# TOP_EFUSE_FARM_TOP_EFUSE_FARM register map
Vendor: Texas Instruments
Peripheral module from a debugger description file (folder AM263).
Registers are 32-bit, access per field, reset values left out (the file's numbers can be read two ways) unless marked. A register's access mark holds for its fields unless they carry their own. Offsets are as the file gives them; lines under a group give offsets from that group; [hi:lo] are bit positions; {n}, {i} and the like mark numbered series; 'fields as' and 'values as' point back to an identical list; <NAME> marks a mode.

## TOP_EFUSE_FARM_TOP_EFUSE_FARM
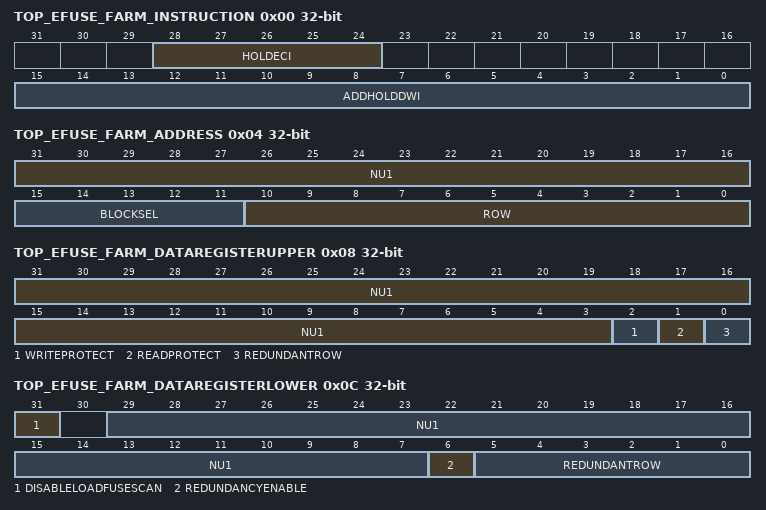
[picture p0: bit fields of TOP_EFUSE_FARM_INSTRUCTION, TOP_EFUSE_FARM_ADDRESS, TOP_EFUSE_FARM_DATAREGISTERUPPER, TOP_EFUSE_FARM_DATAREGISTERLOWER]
0x00 TOP_EFUSE_FARM_INSTRUCTION rw
  [28:24] HOLDECI — Holds the eFuse controller instruction.
  [15:0] ADDHOLDDWI — Holds the address to use for the DumpWord instruction. All other instructions ignore these bits.
0x04 TOP_EFUSE_FARM_ADDRESS
  [31:16] NU1 ro — Not used
  [15:11] BLOCKSEL rw — FuseROM block select. These five bits select which of the 32 possible FuseROMs is used in the following instruction.
  [10:0] ROW rw — FuseROM row address. Given the FuseROM selected by the FuseROM block select, these 11 bits select which row of the FuseROM is used in the following instruction. Since the maximum number of rows for a FuseROM is 64, only bits [5:0] of the FuseROM row address should be used. Address bits [10:6] should be set low ('0')
0x08 TOP_EFUSE_FARM_DATAREGISTERUPPER
  [31:3] NU1 ro — Not used
  [2] WRITEPROTECT rw — Write protect (WP). Once this bit is set high ('1') in any FuseROM row, the other bits in that FuseROM row can no longer be programmed.
  [1] READPROTECT rw — Read protect (RP). Once this bit is set high ('1') in any FuseROM row, a DumpWord instruction returns all zeros (00000000H). The actual data in bits [31:0] of that row will still be loaded into the fuse scan chain during an autoload operation.
  [0] REDUNDANTROW rw — row 0 - Not used row 1 - 63 Redundant (R). Once this bit is set high (?1?), the row is marked as having a failure and is replaced by a redundant row.
0x0C TOP_EFUSE_FARM_DATAREGISTERLOWER
  [31] DISABLELOADFUSESCAN rw — Disable LoadFuseScanChain. If this bit is programmed, the LoadFuseScanChain operation (also called soft load operation) is disabled.
  [29:7] NU1 ro — Not used
  [6] REDUNDANCYENABLE rw — Redundancy enable. If a redundant row address is programmed in bits[5:0], this bit must be programmed.
  [5:0] REDUNDANTROW rw — Redundant row address. These six bits contain the address of a failing row that will be replaced by the native redundant row physically located at the bottom of FuseROM array.
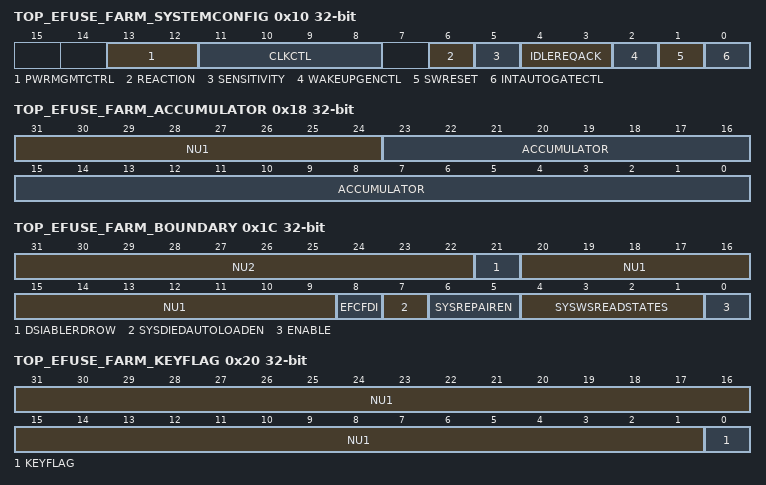
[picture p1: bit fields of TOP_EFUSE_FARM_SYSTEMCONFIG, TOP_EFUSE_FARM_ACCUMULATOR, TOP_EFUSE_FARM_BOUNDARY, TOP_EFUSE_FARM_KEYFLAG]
0x10 TOP_EFUSE_FARM_SYSTEMCONFIG rw
  [13:12] PWRMGMTCTRL — Master interface power management control
  [11:8] CLKCTL — Control of clock internal gating while module is idle. There is one bit per clock. The actual register width depends on the number of functional clocks controlled.
  [6] REACTION — Reaction to module suspend assertion (for emulation). There is no effect if bit[5]=1.
  [5] SENSITIVITY — Sensitivity to module suspend (for emulation).
  [4:3] IDLEREQACK — Slave interface power management control. Idle request/acknowledge control.
  [2] WAKEUPGENCTL — Asynchronous wake-up generation control
  [1] SWRESET — Module software reset
  [0] INTAUTOGATECTL — Internal autogating control.
0x14 TOP_EFUSE_FARM_SYSTEMSTATUS rw
  [0] RESETDONE
0x18 TOP_EFUSE_FARM_ACCUMULATOR
  [31:24] NU1 ro — Not used
  [23:0] ACCUMULATOR rw — Accumulator. These bits hold data after the execution of various instructions.
0x1C TOP_EFUSE_FARM_BOUNDARY
  [31:22] NU2 ro — Not used
  [21] DSIABLERDROW rw — Disable read row 0. When high, disables read of row 0 during initial access of FuseROM.
  [20:9] NU1 ro — Not used
  [8] EFCFDI rw — EFC_FDI. This bit drives the EFC_FDI input when enable is set.
  [7] SYSDIEDAUTOLOADEN rw — SYS_DIEID_AUTOLOAD_EN. This bit drives the SYS_DIEID_AUTOLOAD_EN input when enable is set.
  [6:5] SYSREPAIREN rw — SYS_REPAIR_EN[1:0]. This bus sets the SYS_REPAIR_EN inputs when enable is set.
  [4:1] SYSWSREADSTATES rw — SYS_WS_READ_STATES[3:0]. These bits drive the SYS_WS_READ_STATES inputs when enable is set.
  [0] ENABLE rw — Enable. This bit is used to control whether the input ports or the boundary register drives the inputs. If set high (?1?), the inputs to the controller are driven by the values of the boundary register.
0x20 TOP_EFUSE_FARM_KEYFLAG
  [31:1] NU1 ro — Not used
  [0] KEYFLAG rw — Key flag. If the proper key is loaded into the key code bits, this bit will read a 1.
0x24 TOP_EFUSE_FARM_KEY rw
  [31:0] KEYCODE — Key code. These 32 bits are used to set the key (96969696h) for the program instruction.
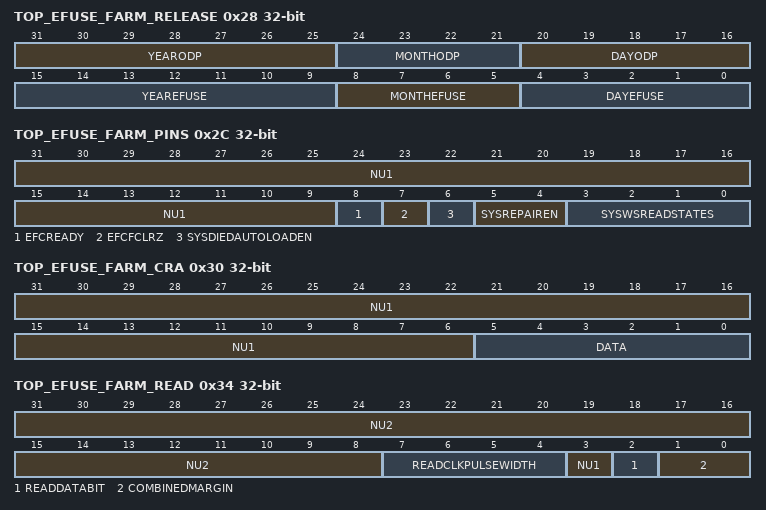
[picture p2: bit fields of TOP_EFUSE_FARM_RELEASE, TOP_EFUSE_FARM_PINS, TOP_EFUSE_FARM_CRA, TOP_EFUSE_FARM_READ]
0x28 TOP_EFUSE_FARM_RELEASE rw
  [31:25] YEARODP — Release code indicating year of ODP controller macro release.
  [24:21] MONTHODP — Release code indicating month of ODP controller macro release.
  [20:16] DAYODP — Release code indicating day of ODP controller macro release.
  [15:9] YEAREFUSE — Release code indicating year of eFuse controller macro release.
  [8:5] MONTHEFUSE — Release code indicating month of eFuse controller macro release.
  [4:0] DAYEFUSE — Release code indicating day of eFuse controller macro release.
0x2C TOP_EFUSE_FARM_PINS
  [31:9] NU1 ro — Not used
  [8] EFCREADY rw — EFC_READY. Output pin.
  [7] EFCFCLRZ rw — EFC_FCLRZ. Output pin.
  [6] SYSDIEDAUTOLOADEN rw — SYS_DIEID_AUTOLOAD_EN. Input pin.
  [5:4] SYSREPAIREN rw — SYS_REPAIR_EN[1:0]. Input pins.
  [3:0] SYSWSREADSTATES rw — SYS_WS_READ_STATES[3:0]. Input pin.
0x30 TOP_EFUSE_FARM_CRA
  [31:6] NU1 ro — Not used
  [5:0] DATA rw — Data bits to be programmed into the CRA bits of the addressed row
0x34 TOP_EFUSE_FARM_READ
  [31:8] NU2 ro — Not used
  [7:4] READCLKPULSEWIDTH rw — ROM clock read pulse width. Active high. Specifies the number of internal clock cycles that the FuseROM clock (pin FROM_CLK) is high ('1'). These bits override the SYS_WS_READ_STATE[3:0] ports. Values are: Bit Width (4b'0000) 1 * SYS_CLK period (4b'0001) 1 * SYS_CLK period (4b'0010) 2 * SYS_CLK period (4b'0011) 3 * SYS_CLK period (4b'0100) 4 * SYS_CLK period (4b?0101) 5 * SYS_CLK period (4b?0110) - (4b?1111) Not used
  [3] NU1 ro — Reserved for FuseROM testing and debugging.
  [2] READDATABIT rw — Read data bit. If the read protect (RP) bit is set in any row, only RP and the write protect (WP) bit are reported during a read, and the other bits are zero. If the RP bit is not set, and the repair (R) bit is set: If read register[2] = 0 (default), then a read command reads data from the redundant repair row. . If read register[2] = 1, then a read command reads data from the original address row.
  [1:0] COMBINEDMARGIN rw — Combined margin. The bits set the sense amp margin limits according to the following table. The FuseROM Compiler section in the GS60 Customer In-field Programmable FuseROM specification shows more information on combined margin. Margin(1:0) Trip Point Label Description 00 5K Normal Normal read 01 2K Margin 0 Margin test for unblown fuses. An unblown fuse should have a resistance below the trip point. 10 22K Margin 1A Margin test for blown fuses. Higher compare resistance than normal. 11 60K Margin 1B Margin test for blown fuses. Higher margin resistance than normal or Margin 1A.
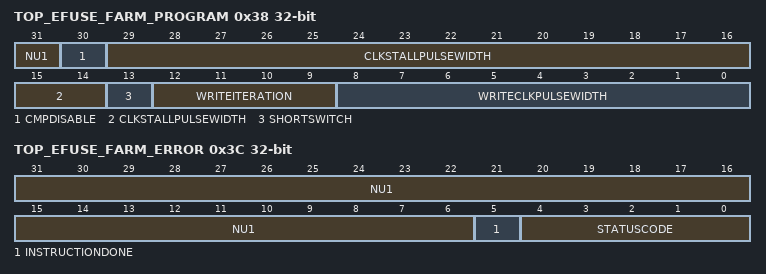
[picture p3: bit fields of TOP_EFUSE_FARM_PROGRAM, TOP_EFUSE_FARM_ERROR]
0x38 TOP_EFUSE_FARM_PROGRAM
  [31] NU1 ro — Not used
  [30] CMPDISABLE rw — Compare disable. Before any FuseROM bit is actually blown, the value of the data register is compared to the FuseROM data bits in the row selected by the address register. If the data register is already equal to the FuseROM row data, the row is not blown, and the program instruction is aborted. Error code 5b 01101 (for more information, see FuseFarm error codes) is placed on EFC_ERROR ports. To avoid this and force the program instruction to continue, set this bit to 1.
  [29:14] CLKSTALLPULSEWIDTH rw — 16-bit FuseROM clock stall pulse width. Active low. After the controller attempts to program the data register value into the FuseROM row selected by the address register, the FROM_CLK signal is held low (?0?) for a specified number of internal clock cycles to separate each pass of the controller. These bits determine the number of clock cycles that the controller pauses between each sweep of the FuseROM row.
  [13] SHORTSWITCH rw — Program signal for FuseROM VPP-to-VDD shorting switch. This bit must be set high before executing the program instruction and low after program is completed. The eFuse controller output FROM_ENSW is created from this signal. The FROM_ENSW signal is used to disable (?1?) and enable (?0?) the FuseROM VPP-to-VDD shorting switch during program operation.
  [12:9] WRITEITERATION rw — 4-bit maximum write iterations. This register sets the maximum number of sweeps that the program instruction uses to make the FuseROM row equal to the value in the data register. If the eFuse controller sweeps the number of times set in the maximum write iterations bits, an error code (5b?00111 or 5b?01000) is reported ((for more information, see FuseFarm error codes), and the program instruction sets the EFC_READY port high (?1?) and JTAG_TDO high (?1?) for one clock cycle.
  [8:0] WRITECLKPULSEWIDTH rw — 9-bit FuseROM clock write pulse width. Active low. These bits determine the width of the write phase (i.e., FROM_CLK = '0') of the FROM_CLK signal. In most instances, the width of the FROM_CLK write phase relative to the internal clock is simply equal to the unsigned decimal equivalent of the binary code. However, when this value is less than or equal to one, the following table should be used: Read pulse width Write pulse width FROM_CLK == '0' FROM_CLK == '1' 000 000000000 raw raw 000 000000001 1 1 001 000000000 1 1 001 000000001 1 1
0x3C TOP_EFUSE_FARM_ERROR
  [31:6] NU1 ro — Not used
  [5] INSTRUCTIONDONE rw — Instruction done. Set after each instruction is done. Should be cleared by the interfaces.
  [4:0] STATUSCODE rw — Error/Status code. These five bits hold the error or status code that was returned by the instruction that was executed.
